AUTOSAR XML (schema 4-0-3)
package /ComponentTypes
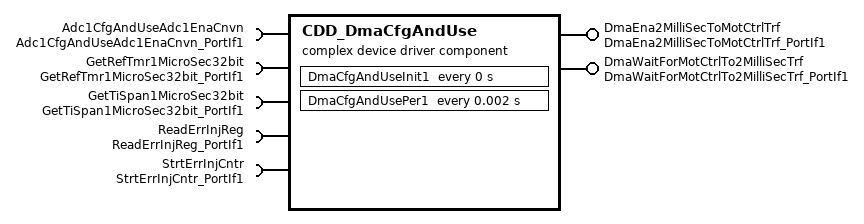
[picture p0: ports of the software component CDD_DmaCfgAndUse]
  complex device driver sw component type CDD_DmaCfgAndUse
    provide port DmaEna2MilliSecToMotCtrlTrf: server-com-spec{operation=Oper, queue-length=1}, provided-interface=DmaEna2MilliSecToMotCtrlTrf_PortIf1
    provide port DmaWaitForMotCtrlTo2MilliSecTrf: server-com-spec{operation=Oper, queue-length=1}, provided-interface=DmaWaitForMotCtrlTo2MilliSecTrf_PortIf1
    5 x require port, all with client-com-spec=Oper:
      Adc1CfgAndUseAdc1EnaCnvn: required-interface=Adc1CfgAndUseAdc1EnaCnvn_PortIf1
      GetRefTmr1MicroSec32bit: required-interface=GetRefTmr1MicroSec32bit_PortIf1
      GetTiSpan1MicroSec32bit: required-interface=GetTiSpan1MicroSec32bit_PortIf1
      ReadErrInjReg: required-interface=ReadErrInjReg_PortIf1  # Read BRAMDAT2
      StrtErrInjCntr: required-interface=StrtErrInjCntr_PortIf1
    behavior CDD_DmaCfgAndUse_InternalBehavior
      ar-typed-per-instance-memorys:
        data d2MilliSecAdcActDmaTrfTi: sw-calibration-access=READ-ONLY, type=uint32  # Display variable used to help understand the Actual Dma Transfer time
        data DmaCfgAndUse2MilliSecAdcMaxDmaTrfTi: sw-calibration-access=READ-ONLY, type=uint32  # Display variable used to help understand the Maximum Dma Transfer time
        data DmaCfgAndUse2MilliSecAdcStrtTi: sw-calibration-access=READ-ONLY, type=uint32  # ADC Conversion transfer start time
      timing event CDD_DmaCfgAndUse_InitEvent: start-on-event=DmaCfgAndUseInit1, period=0
      timing event TMT_DmaCfgAndUsePer1: start-on-event=DmaCfgAndUsePer1, period=0.002
      operation invoked event OIT_DmaEna2MilliSecToMotCtrlTrf_Oper_DmaEna2MilliSecToMotCtrlTrf_Oper: start-on-event=DmaEna2MilliSecToMotCtrlTrf_Oper, operation=DmaEna2MilliSecToMotCtrlTrf.Oper
      operation invoked event OIT_DmaWaitForMotCtrlTo2MilliSecTrf_Oper_DmaWaitForMotCtrlTo2MilliSecTrf_Oper: start-on-event=DmaWaitForMotCtrlTo2MilliSecTrf_Oper, operation=DmaWaitForMotCtrlTo2MilliSecTrf.Oper
      4 x runnable:
        DmaCfgAndUseInit1  # DMA Configuration and Usage
        DmaCfgAndUsePer1
          sync call SC_Adc1CfgAndUseAdc1EnaCnvn_Oper: operation=Adc1CfgAndUseAdc1EnaCnvn.Oper, timeout=0
          sync call SC_GetRefTmr1MicroSec32bit_Oper: operation=GetRefTmr1MicroSec32bit.Oper, timeout=0
        DmaEna2MilliSecToMotCtrlTrf_Oper
          sync call SC_ReadErrInjReg_Oper: operation=ReadErrInjReg.Oper, timeout=0
          sync call SC_StrtErrInjCntr_Oper_1: operation=StrtErrInjCntr.Oper, timeout=0
        DmaWaitForMotCtrlTo2MilliSecTrf_Oper
          sync call SC_GetTiSpan1MicroSec32bit_Oper: operation=GetTiSpan1MicroSec32bit.Oper, timeout=0
  swc implementation CDD_DmaCfgAndUse_Implementation: behavior=CDD_DmaCfgAndUse_InternalBehavior
    code-descriptors:
      code Default: artifact-descriptors=autosar-engineering-object={short-label=Default, category=SWSRC}
